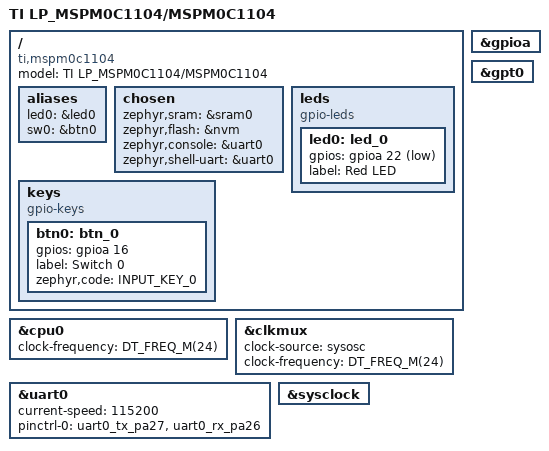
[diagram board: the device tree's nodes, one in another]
/* SPDX-License-Identifier: Apache-2.0 */

/dts-v1/;

#include <ti/mspm0c110x/mspm0c1104.dtsi>
#include <ti/mspm0c110x/mspm0c110x-pinctrl.dtsi>
#include <zephyr/dt-bindings/input/input-event-codes.h>
#include <zephyr/dt-bindings/adc/mspm0_adc.h>
#include <zephyr/dt-bindings/pwm/pwm.h>
#include <zephyr/dt-bindings/clock/mspm0_clock.h>

/ {
	model = "TI LP_MSPM0C1104/MSPM0C1104";
	compatible = "ti,mspm0c1104";

	aliases {
		led0 = &led0;
		sw0 = &btn0;
	};

	chosen {
		zephyr,sram = &sram0;
		zephyr,flash = &nvm;
		zephyr,console = &uart0;
		zephyr,shell-uart = &uart0;
	};

	leds {
		compatible = "gpio-leds";
		led0: led_0 {
			gpios = <&gpioa 22 GPIO_ACTIVE_LOW>;
			label = "Red LED";
		};
	};

	keys {
		compatible = "gpio-keys";
		btn0: btn_0 {
			gpios = <&gpioa 16 GPIO_ACTIVE_HIGH>;
			label = "Switch 0";
			zephyr,code = <INPUT_KEY_0>;
		};
	};
};

&cpu0 {
	clock-frequency = <DT_FREQ_M(24)>;
};

&clkmux {
	clock-source = <&sysosc>;
	clock-frequency = <DT_FREQ_M(24)>;
};

&gpioa {
	status = "okay";
};

&uart0 {
	status = "okay";
	current-speed = <115200>;
	pinctrl-0 = <&uart0_tx_pa27 &uart0_rx_pa26>;
	pinctrl-names = "default";
};

&gpt0 {
	status = "okay";

};

&sysclock {
	status = "okay";
};
